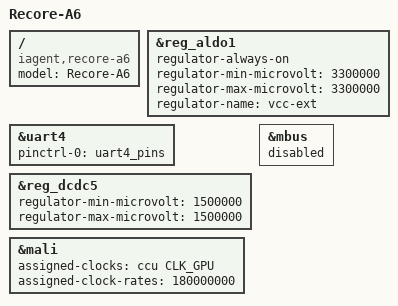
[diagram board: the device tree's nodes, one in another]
// SPDX-License-Identifier: (GPL-2.0+ OR MIT)

/dts-v1/;

#include "sun50i-a64-recore.dtsi"

/ {
	model = "Recore-A6";
	compatible = "iagent,recore-a6", "allwinner,sun50i-a64";
};

&reg_aldo1 {
	regulator-always-on;
	regulator-min-microvolt = <3300000>;
	regulator-max-microvolt = <3300000>;
	regulator-name = "vcc-ext";
};
&uart4 {
	pinctrl-names = "default";
	pinctrl-0 = <&uart4_pins>;
	status = "okay";
};

&reg_dcdc5 {
	regulator-min-microvolt = <1500000>;
	regulator-max-microvolt = <1500000>;
};

&mali {
	/delete-property/ operating-points-v2;
	assigned-clocks = <&ccu CLK_GPU>;
	assigned-clock-rates = <180000000>;
};

&mbus {
	status = "disabled";
};
